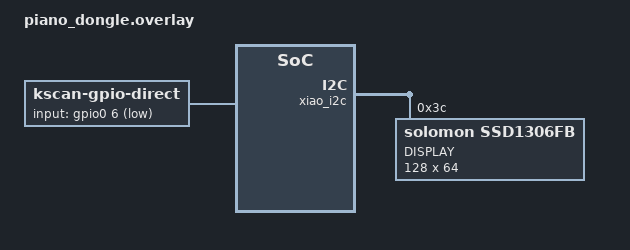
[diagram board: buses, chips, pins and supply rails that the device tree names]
/*
 * Copyright (c) 2020 The ZMK Contributors
 *
 * SPDX-License-Identifier: MIT
 */

#include "piano.dtsi"

/ {
        chosen {
	        zephyr,display = &oled;
	};

	kscan0: kscan {
		compatible = "zmk,kscan-gpio-direct";
		label = "KSCAN";
		input-gpios = <&gpio0 6 (GPIO_ACTIVE_LOW | GPIO_PULL_DOWN)>;
	};
};
&xiao_i2c {
    status = "okay";

    oled: ssd1306@3c {
        compatible = "solomon,ssd1306fb";
        reg = <0x3c>;
        label = "DISPLAY";
        width = <128>;
        height = <64>;
        segment-offset = <0>;
        page-offset = <0>;
        display-offset = <0>;
        multiplex-ratio = <63>;
        prechargep = <0x22>;
    };
};
&xiao_spi { status = "disabled"; };
&xiao_serial { status = "disabled"; };
